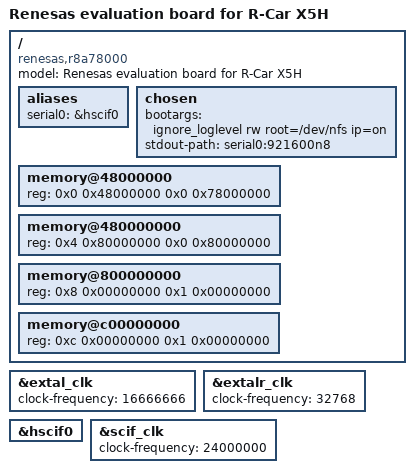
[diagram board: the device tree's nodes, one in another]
// SPDX-License-Identifier: GPL-2.0
/*
 * Device Tree Source extras for U-Boot
 *
 * Copyright (C) 2023 Renesas Electronics Corp.
 */

/dts-v1/;
#include "r8a78000.dtsi"
#include "r8a78000-u-boot.dtsi"

/ {
	model = "Renesas evaluation board for R-Car X5H";
	compatible = "renesas,r8a78000";

	aliases {
		serial0 = &hscif0;
	};

	chosen {
		bootargs = "ignore_loglevel rw root=/dev/nfs ip=on";
		stdout-path = "serial0:921600n8";
	};

	memory@48000000 {
		device_type = "memory";
		/* first 128MB is reserved for secure area. */
		reg = <0x0 0x48000000 0x0 0x78000000>;
	};

	memory@480000000 {
		device_type = "memory";
		reg = <0x4 0x80000000 0x0 0x80000000>;
	};

	memory@800000000 {
		device_type = "memory";
		reg = <0x8 0x00000000 0x1 0x00000000>;
	};

	memory@c00000000 {
		device_type = "memory";
		reg = <0xc 0x00000000 0x1 0x00000000>;
	};
};

&extal_clk {
	clock-frequency = <16666666>;
};

&extalr_clk {
	clock-frequency = <32768>;
};

&hscif0 {
	status = "okay";
};

&scif_clk {
	clock-frequency = <24000000>;
};
